VERSION ""

NS_ :

BS_:

BU_: XXX

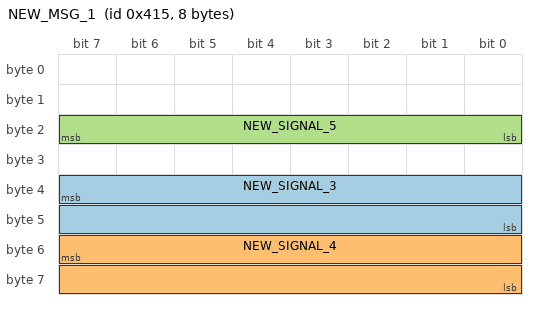
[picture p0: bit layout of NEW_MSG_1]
BO_ 1045 NEW_MSG_1: 8 XXX
 SG_ NEW_SIGNAL_3 : 39|16@0+ (1,0) [0|65535] "" XXX
 SG_ NEW_SIGNAL_4 : 55|16@0+ (1,0) [0|65535] "" XXX
 SG_ NEW_SIGNAL_5 : 23|8@0+ (1,0) [0|255] "" XXX

BO_ 122 steering_cmd?: 8 XXX
 SG_ NEW_SIGNAL_1 : 31|8@0+ (1,0) [0|255] "" XXX
 SG_ NEW_SIGNAL_2 : 15|8@0+ (1,0) [0|255] "" XXX

BO_ 118 steering?: 8 XXX
 SG_ NEW_SIGNAL_1 : 7|8@0+ (1,0) [0|255] "" XXX
 SG_ steering : 15|8@0+ (1,0) [0|255] "" XXX

BO_ 119 NEW_MSG_3: 8 XXX
 SG_ NEW_SIGNAL_1 : 23|8@0+ (1,0) [0|255] "" XXX
 SG_ NEW_SIGNAL_2 : 31|8@0+ (1,0) [0|255] "" XXX
